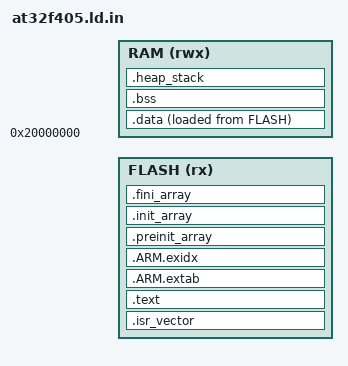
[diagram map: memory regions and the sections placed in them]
/* SPDX-License-Identifier: MIT */
ENTRY(Reset_Handler)
MEMORY {
  FLASH (rx) : ORIGIN = @FLASH_ORIGIN@, LENGTH = @FLASH_KB@K
  RAM (rwx) : ORIGIN = 0x20000000, LENGTH = @RAM_KB@K - 8
}
/* Keep the stack 8-byte aligned and preserve the double-reset word. */
_estack = ORIGIN(RAM) + LENGTH(RAM);
_board_dfu_dbl_tap = _estack + 4;
SECTIONS {
  .isr_vector : { KEEP(*(.isr_vector)) } > FLASH
  .text : {
    *(.text*) *(.rodata*)
    KEEP(*(.init)) KEEP(*(.fini))
    . = ALIGN(4);
  } > FLASH
  .ARM.extab : { *(.ARM.extab*) } > FLASH
  .ARM.exidx : {
    __exidx_start = .; *(.ARM.exidx*) __exidx_end = .;
  } > FLASH
  .preinit_array : {
    __preinit_array_start = .; KEEP(*(.preinit_array*)) __preinit_array_end = .;
  } > FLASH
  .init_array : {
    __init_array_start = .; KEEP(*(SORT(.init_array.*))) KEEP(*(.init_array)) __init_array_end = .;
  } > FLASH
  .fini_array : {
    __fini_array_start = .; KEEP(*(SORT(.fini_array.*))) KEEP(*(.fini_array)) __fini_array_end = .;
  } > FLASH
  _sidata = LOADADDR(.data);
  .data : {
    . = ALIGN(4); _sdata = .; *(.data*) . = ALIGN(4); _edata = .;
  } > RAM AT > FLASH
  .bss (NOLOAD) : {
    . = ALIGN(4); _sbss = .; *(.bss*) *(COMMON) . = ALIGN(4); _ebss = .;
  } > RAM
  .heap_stack (NOLOAD) : {
    . = ALIGN(8); _end = .; PROVIDE(end = .); . += 0x1000;
  } > RAM
  ASSERT(_estack >= ADDR(.heap_stack) + SIZEOF(.heap_stack), "Insufficient stack space")
}
